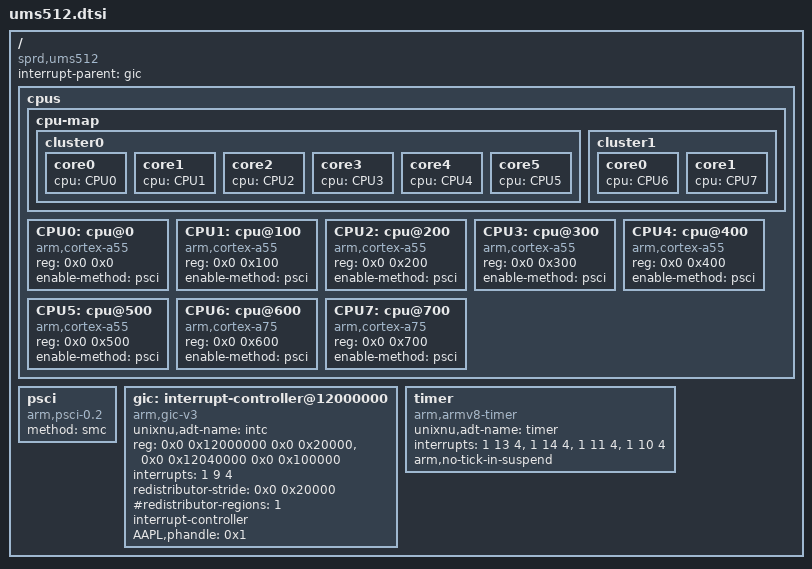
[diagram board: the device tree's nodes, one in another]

/*
 * Unisoc UMS512 / SharkL5Pro shared device tree.
 *
 * Target board:
 *   Realme C21Y RMX3261
 *   SoC: Unisoc T610 / UMS512
 *   Board family: ums512_1h10
 *
 * Based on:
 *   realme-kernel-opensource/
 *   realme_C21Y-AndroidR-kernel-source
 *
 * Shared SoC definitions only.
 * DRAM, reserved-memory, UART, storage, display and peripherals
 * must be defined by the board-specific DTS.
 */

/ {
    compatible = "sprd,ums512";
    #address-cells = <2>;
    #size-cells = <2>;

    interrupt-parent = <&gic>;

    cpus {
        #address-cells = <2>;
        #size-cells = <0>;

        cpu-map {
            cluster0 {
                core0 { cpu = <&CPU0>; };
                core1 { cpu = <&CPU1>; };
                core2 { cpu = <&CPU2>; };
                core3 { cpu = <&CPU3>; };
                core4 { cpu = <&CPU4>; };
                core5 { cpu = <&CPU5>; };
            };

            cluster1 {
                core0 { cpu = <&CPU6>; };
                core1 { cpu = <&CPU7>; };
            };
        };

        CPU0: cpu@0 {
            device_type = "cpu";
            compatible = "arm,cortex-a55", "arm,armv8";
            reg = <0x0 0x0>;
            enable-method = "psci";
        };

        CPU1: cpu@100 {
            device_type = "cpu";
            compatible = "arm,cortex-a55", "arm,armv8";
            reg = <0x0 0x100>;
            enable-method = "psci";
        };

        CPU2: cpu@200 {
            device_type = "cpu";
            compatible = "arm,cortex-a55", "arm,armv8";
            reg = <0x0 0x200>;
            enable-method = "psci";
        };

        CPU3: cpu@300 {
            device_type = "cpu";
            compatible = "arm,cortex-a55", "arm,armv8";
            reg = <0x0 0x300>;
            enable-method = "psci";
        };

        CPU4: cpu@400 {
            device_type = "cpu";
            compatible = "arm,cortex-a55", "arm,armv8";
            reg = <0x0 0x400>;
            enable-method = "psci";
        };

        CPU5: cpu@500 {
            device_type = "cpu";
            compatible = "arm,cortex-a55", "arm,armv8";
            reg = <0x0 0x500>;
            enable-method = "psci";
        };

        CPU6: cpu@600 {
            device_type = "cpu";
            compatible = "arm,cortex-a75", "arm,armv8";
            reg = <0x0 0x600>;
            enable-method = "psci";
        };

        CPU7: cpu@700 {
            device_type = "cpu";
            compatible = "arm,cortex-a75", "arm,armv8";
            reg = <0x0 0x700>;
            enable-method = "psci";
        };
    };

    psci {
        compatible = "arm,psci-0.2";
        method = "smc";
    };

    gic: interrupt-controller@12000000 {
        compatible = "arm,gic-v3";

        unixnu,adt-name = "intc";

        #interrupt-cells = <3>;
        #address-cells = <2>;
        #size-cells = <2>;

        ranges;

        reg = <0x0 0x12000000 0x0 0x20000>,
              <0x0 0x12040000 0x0 0x100000>;

        interrupts = <1 9 4>;

        redistributor-stride = <0x0 0x20000>;
        #redistributor-regions = <1>;

        interrupt-controller;

        AAPL,phandle = <0x1>;
    };

    timer {
        compatible = "arm,armv8-timer";

        unixnu,adt-name = "timer";

        interrupts = <1 13 4>,
                     <1 14 4>,
                     <1 11 4>,
                     <1 10 4>;

        arm,no-tick-in-suspend;
    };
};
